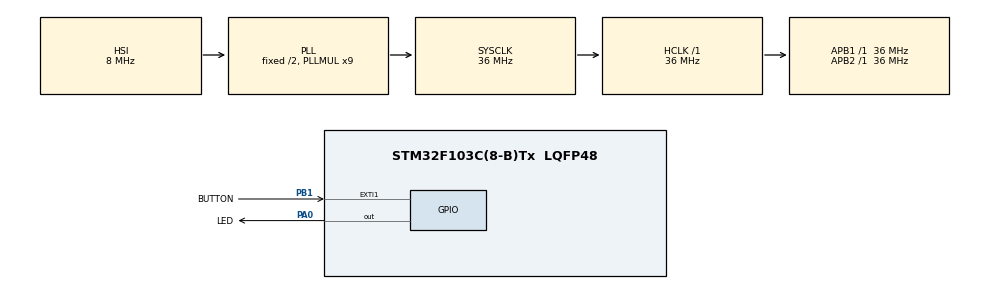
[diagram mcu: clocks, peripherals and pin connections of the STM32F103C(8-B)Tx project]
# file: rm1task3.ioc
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Mcu.Family=STM32F1
Mcu.Name=STM32F103C(8-B)Tx
Mcu.Package=LQFP48
NVIC.EXTI1_IRQn=true\:1\:0\:true\:false\:true\:true\:true\:true
NVIC.PriorityGroup=NVIC_PRIORITYGROUP_4
NVIC.TIM3_IRQn=true\:2\:0\:true\:false\:true\:true\:true\:true
PA0-WKUP.GPIO_Label=LED
PA0-WKUP.PinState=GPIO_PIN_RESET
PA0-WKUP.Signal=GPIO_Output
PA13.Mode=Serial_Wire
PA13.Signal=SYS_JTMS-SWDIO
PA14.Mode=Serial_Wire
PA14.Signal=SYS_JTCK-SWCLK
PB1.GPIO_Label=BUTTON
PB1.GPIO_ModeDefaultEXTI=GPIO_MODE_IT_FALLING
PB1.GPIO_PuPd=GPIO_PULLUP
PB1.Signal=GPXTI1
ProjectManager.HeapSize=0x200
ProjectManager.StackSize=0x400
ProjectManager.TargetToolchain=MDK-ARM V5.32
RCC.AHBFreq_Value=36000000
RCC.APB1Freq_Value=36000000
RCC.APB1TimFreq_Value=36000000
RCC.APB2Freq_Value=36000000
RCC.APB2TimFreq_Value=36000000
RCC.HCLKFreq_Value=36000000
RCC.PLLMUL=RCC_PLL_MUL9
RCC.SYSCLKFreq_VALUE=36000000
RCC.SYSCLKSource=RCC_SYSCLKSOURCE_PLLCLK
RCC.USBFreq_Value=36000000
TIM3.AutoReloadPreload=TIM_AUTORELOAD_PRELOAD_ENABLE
TIM3.Period=199
TIM3.Prescaler=3599
VP_TIM3_VS_ClockSourceINT.Mode=Internal
board=custom

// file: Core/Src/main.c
/* USER CODE BEGIN Header */
/**
  ******************************************************************************
  * @file           : main.c
  * @brief          : Main program body
  ******************************************************************************
  * @attention
  *
  * Copyright (c) 2026 STMicroelectronics.
  * All rights reserved.
  *
  * This software is licensed under terms that can be found in the LICENSE file
  * in the root directory of this software component.
  * If no LICENSE file comes with this software, it is provided AS-IS.
  *
  ******************************************************************************
  */
/* USER CODE END Header */
#include "main.h"

TIM_HandleTypeDef htim3;

/* USER CODE BEGIN PV */
volatile uint8_t button_xiaodou=0;//让编译知道看中断函数，不优化掉
/* USER CODE END PV */

void SystemClock_Config(void);
static void MX_GPIO_Init(void);
static void MX_TIM3_Init(void);

int main(void)
{

  /* MCU Configuration--------------------------------------------------------*/

  /* Reset of all peripherals, Initializes the Flash interface and the Systick. */
  HAL_Init();

  /* Configure the system clock */
  SystemClock_Config();

  /* Initialize all configured peripherals */
  MX_GPIO_Init();
  MX_TIM3_Init();

  /* Infinite loop */
  while (1)
  {

  }
}

void SystemClock_Config(void)
{
  RCC_OscInitTypeDef RCC_OscInitStruct = {0};
  RCC_ClkInitTypeDef RCC_ClkInitStruct = {0};

  /** Initializes the RCC Oscillators according to the specified parameters
  * in the RCC_OscInitTypeDef structure.
  */
  RCC_OscInitStruct.OscillatorType = RCC_OSCILLATORTYPE_HSI;
  RCC_OscInitStruct.HSIState = RCC_HSI_ON;
  RCC_OscInitStruct.HSICalibrationValue = RCC_HSICALIBRATION_DEFAULT;
  RCC_OscInitStruct.PLL.PLLState = RCC_PLL_ON;
  RCC_OscInitStruct.PLL.PLLSource = RCC_PLLSOURCE_HSI_DIV2;
  RCC_OscInitStruct.PLL.PLLMUL = RCC_PLL_MUL9;
  if (HAL_RCC_OscConfig(&RCC_OscInitStruct) != HAL_OK)
  {
    Error_Handler();
  }

  /** Initializes the CPU, AHB and APB buses clocks
  */
  RCC_ClkInitStruct.ClockType = RCC_CLOCKTYPE_HCLK|RCC_CLOCKTYPE_SYSCLK
                              |RCC_CLOCKTYPE_PCLK1|RCC_CLOCKTYPE_PCLK2;
  RCC_ClkInitStruct.SYSCLKSource = RCC_SYSCLKSOURCE_PLLCLK;
  RCC_ClkInitStruct.AHBCLKDivider = RCC_SYSCLK_DIV1;
  RCC_ClkInitStruct.APB1CLKDivider = RCC_HCLK_DIV1;
  RCC_ClkInitStruct.APB2CLKDivider = RCC_HCLK_DIV1;

  if (HAL_RCC_ClockConfig(&RCC_ClkInitStruct, FLASH_LATENCY_1) != HAL_OK)
  {
    Error_Handler();
  }
}

static void MX_TIM3_Init(void)
{

  TIM_ClockConfigTypeDef sClockSourceConfig = {0};
  TIM_MasterConfigTypeDef sMasterConfig = {0};

  htim3.Instance = TIM3;
  htim3.Init.Prescaler = 3599;
  htim3.Init.CounterMode = TIM_COUNTERMODE_UP;
  htim3.Init.Period = 199;
  htim3.Init.ClockDivision = TIM_CLOCKDIVISION_DIV1;
  htim3.Init.AutoReloadPreload = TIM_AUTORELOAD_PRELOAD_ENABLE;
  if (HAL_TIM_Base_Init(&htim3) != HAL_OK)
  {
    Error_Handler();
  }
  sClockSourceConfig.ClockSource = TIM_CLOCKSOURCE_INTERNAL;
  if (HAL_TIM_ConfigClockSource(&htim3, &sClockSourceConfig) != HAL_OK)
  {
    Error_Handler();
  }
  sMasterConfig.MasterOutputTrigger = TIM_TRGO_RESET;
  sMasterConfig.MasterSlaveMode = TIM_MASTERSLAVEMODE_DISABLE;
  if (HAL_TIMEx_MasterConfigSynchronization(&htim3, &sMasterConfig) != HAL_OK)
  {
    Error_Handler();
  }

}

static void MX_GPIO_Init(void)
{
  GPIO_InitTypeDef GPIO_InitStruct = {0};

  /* GPIO Ports Clock Enable */
  __HAL_RCC_GPIOA_CLK_ENABLE();
  __HAL_RCC_GPIOB_CLK_ENABLE();

  /*Configure GPIO pin Output Level */
  HAL_GPIO_WritePin(LED_GPIO_Port, LED_Pin, GPIO_PIN_RESET);

  /*Configure GPIO pin : LED_Pin */
  GPIO_InitStruct.Pin = LED_Pin;
  GPIO_InitStruct.Mode = GPIO_MODE_OUTPUT_PP;
  GPIO_InitStruct.Pull = GPIO_NOPULL;
  GPIO_InitStruct.Speed = GPIO_SPEED_FREQ_LOW;
  HAL_GPIO_Init(LED_GPIO_Port, &GPIO_InitStruct);

  /*Configure GPIO pin : BUTTON_Pin */
  GPIO_InitStruct.Pin = BUTTON_Pin;
  GPIO_InitStruct.Mode = GPIO_MODE_IT_FALLING;
  GPIO_InitStruct.Pull = GPIO_PULLUP;
  HAL_GPIO_Init(BUTTON_GPIO_Port, &GPIO_InitStruct);

  /* EXTI interrupt init*/
  HAL_NVIC_SetPriority(EXTI1_IRQn, 1, 0);
  HAL_NVIC_EnableIRQ(EXTI1_IRQn);

}

/* USER CODE BEGIN 4 */
void HAL_GPIO_EXTI_Callback(uint16_t GPIO_Pin)
{
  {
		/*这里曾经手欠整了个识别TIM3，气笑了编译才想起来啥也不是*/
    if(GPIO_Pin==BUTTON_Pin)
    {
      if(button_xiaodou==0)//这一段是测试失败之后ds给我纠正的，防止中断反复触发扰乱主循环，导致消抖失效
      /*此外，ds还说这里应该加上一句
      if(GPIO_Pin==BUTTON_Pin)，防止别的按钮使用同一个中断通道而不是PB1
		  这里就连了一个，我认为无所谓,后面有了再加上，keil确实给我报警了*/
      /*老实了，出bug了......*/
      {
        button_xiaodou=1;
        /*HAL_TIM_Base_Start_IT(&htim3)*/;//开计时器，要是溢出了往下走，如果没溢出就被“按下去”那就回来，进不去if，无效
        if(HAL_TIM_Base_Start_IT(&htim3)!=HAL_OK)
          Error_Handler();//忽然想起来作业2我是这么开定时器的，虽然不知道什么时候这个if判断会生效，干脆统一了
      }
    }
  }
}
void HAL_TIM_PeriodElapsedCallback(TIM_HandleTypeDef *htim) //依旧是作业2同款计时器溢出往这转
/*感谢老登的讲解，*htim是收任何定时器地址，承接的是开定时器交出去的&htim3，我的指针依旧依托*/
{
  if(htim->Instance==TIM3)//同作业2
  {
		HAL_TIM_Base_Stop_IT(&htim3);
		/*经过测试之后，有一定概率出现松手led灯恢复原状的情况
		dsh排查之后认为是消抖逻辑不充分，此处没有读取PB1的状态*/
		if(HAL_GPIO_ReadPin(GPIOB,GPIO_PIN_1)==GPIO_PIN_RESET)
		{
			HAL_GPIO_TogglePin(GPIOA,GPIO_PIN_0);
		}
    __HAL_TIM_SET_COUNTER(&htim3,0);//666这里开头是加两个下划线啊，找半天不知道错哪了
    button_xiaodou=0;//一切重置，从零开始
  }
}
/* USER CODE END 4 */

void Error_Handler(void)
{
  __disable_irq();
  while (1)
  {
  }
}
